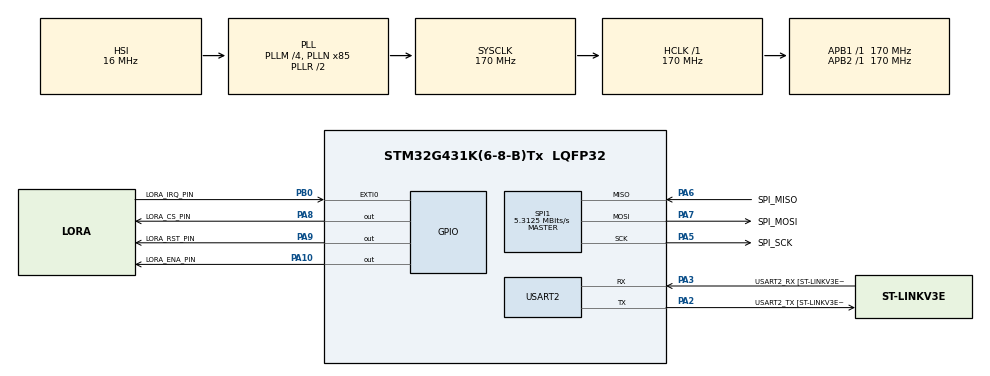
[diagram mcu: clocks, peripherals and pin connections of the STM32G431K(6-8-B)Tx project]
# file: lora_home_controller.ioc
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Mcu.Family=STM32G4
Mcu.Name=STM32G431K(6-8-B)Tx
Mcu.Package=LQFP32
NVIC.EXTI0_IRQn=true\:0\:0\:false\:false\:true\:true\:true\:true
NVIC.PriorityGroup=NVIC_PRIORITYGROUP_4
NVIC.SPI1_IRQn=true\:0\:0\:false\:false\:true\:true\:true\:true
NVIC.USART2_IRQn=true\:0\:0\:false\:false\:true\:true\:true\:true
PA10.GPIO_Label=LORA_ENA_PIN
PA10.Signal=GPIO_Output
PA13.GPIO_Label=T_SWDIO
PA13.Signal=SYS_JTMS-SWDIO
PA14.GPIO_Label=T_SWCLK
PA14.Signal=SYS_JTCK-SWCLK
PA2.GPIO_Label=USART2_TX [ST-LINKV3E_VCP_RX]
PA2.Mode=Asynchronous
PA2.Signal=USART2_TX
PA3.GPIO_Label=USART2_RX [ST-LINKV3E_VCP_TX]
PA3.Mode=Asynchronous
PA3.Signal=USART2_RX
PA5.GPIO_Label=SPI_SCK
PA5.GPIO_Speed=GPIO_SPEED_FREQ_VERY_HIGH
PA5.Mode=Full_Duplex_Master
PA5.Signal=SPI1_SCK
PA6.GPIO_Label=SPI_MISO
PA6.GPIO_Speed=GPIO_SPEED_FREQ_VERY_HIGH
PA6.Mode=Full_Duplex_Master
PA6.Signal=SPI1_MISO
PA7.GPIO_Label=SPI_MOSI
PA7.GPIO_PuPd=GPIO_NOPULL
PA7.GPIO_Speed=GPIO_SPEED_FREQ_VERY_HIGH
PA7.Mode=Full_Duplex_Master
PA7.Signal=SPI1_MOSI
PA8.GPIO_Label=LORA_CS_PIN
PA8.Signal=GPIO_Output
PA9.GPIO_Label=LORA_RST_PIN
PA9.Signal=GPIO_Output
PB0.GPIO_Label=LORA_IRQ_PIN
PB0.Signal=GPXTI0
PB3.GPIO_Label=T_SWO
PB3.Signal=SYS_JTDO-SWO
ProjectManager.HeapSize=0x200
ProjectManager.StackSize=0x400
ProjectManager.TargetToolchain=CMake
RCC.ADC12Freq_Value=170000000
RCC.AHBFreq_Value=170000000
RCC.APB1Freq_Value=170000000
RCC.APB1TimFreq_Value=170000000
RCC.APB2Freq_Value=170000000
RCC.APB2TimFreq_Value=170000000
RCC.CortexFreq_Value=170000000
RCC.EXTERNAL_CLOCK_VALUE=12288000
RCC.HCLKFreq_Value=170000000
RCC.HSE_VALUE=8000000
RCC.HSI48_VALUE=48000000
RCC.HSI_VALUE=16000000
RCC.LSE_VALUE=32768
RCC.PLLM=RCC_PLLM_DIV4
RCC.PLLN=85
RCC.SYSCLKFreq_VALUE=170000000
RCC.SYSCLKSource=RCC_SYSCLKSOURCE_PLLCLK
RCC.USBFreq_Value=170000000
RCC.VCOOutputFreq_Value=340000000
SPI1.BaudRatePrescaler=SPI_BAUDRATEPRESCALER_32
SPI1.CalculateBaudRate=5.3125 MBits/s
SPI1.DataSize=SPI_DATASIZE_8BIT
SPI1.Direction=SPI_DIRECTION_2LINES
SPI1.Mode=SPI_MODE_MASTER
SPI1.VirtualType=VM_MASTER
USART2.VirtualMode-Asynchronous=VM_ASYNC
VP_SYS_VS_DBSignals.Mode=DisableDeadBatterySignals
board=NUCLEO-G431KB

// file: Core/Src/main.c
/* USER CODE BEGIN Header */
/**
  ******************************************************************************
  * @file           : main.c
  * @brief          : Main program body
  ******************************************************************************
  * @attention
  *
  * Copyright (c) 2025 STMicroelectronics.
  * All rights reserved.
  *
  * This software is licensed under terms that can be found in the LICENSE file
  * in the root directory of this software component.
  * If no LICENSE file comes with this software, it is provided AS-IS.
  *
  ******************************************************************************
  */
/* USER CODE END Header */
#include "main.h"
#include "LoRa.h"
#include "lora_engine.h"
#include "spi.h"
#include "stm32g4xx_hal.h"
#include "usart.h"
#include "gpio.h"

/* USER CODE BEGIN PD */
#define MY_NODE_ID 1
// #define MY_NODE_ID 2

LoRa lora;
LoraDriver lora_driver;
LoraEngine lora_engine;

uint8_t lora_receive_flag = 0;
/* USER CODE END PD */

/* USER CODE BEGIN PM */
uint8_t lora_driver_transmit_func(uint8_t* data, uint8_t length, uint16_t timeout)
{
    return LoRa_single_transmit(&lora, data, length, timeout);
}
/* USER CODE END PM */

void SystemClock_Config(void);

/* USER CODE BEGIN 0 */
void HAL_GPIO_EXTI_Callback(uint16_t GPIO_Pin)
{
  if (GPIO_Pin == LORA_IRQ_PIN_Pin)
  {
    lora_receive_flag = 1;
  }
}

/* USER CODE END 0 */

int main(void)
{

  /* MCU Configuration--------------------------------------------------------*/

  /* Reset of all peripherals, Initializes the Flash interface and the Systick. */
  HAL_Init();

  /* Configure the system clock */
  SystemClock_Config();

  /* Initialize all configured peripherals */
  MX_GPIO_Init();
  MX_SPI1_Init();
  MX_USART2_UART_Init();

  /* Infinite loop */
  /* USER CODE BEGIN WHILE */

  // STEP 1) setup lora object
  // if(!SetupLoraWithPins(&lora,
  //     LORA_CS_PIN_GPIO_Port,
  //     LORA_CS_PIN_Pin,
  //     LORA_RST_PIN_GPIO_Port,
  //     LORA_RST_PIN_Pin,
  //     LORA_IRQ_PIN_GPIO_Port,
  //     LORA_IRQ_PIN_Pin,
  //     LORA_ENA_PIN_GPIO_Port,
  //     LORA_ENA_PIN_Pin,
  //     &hspi1))
  // {
  //   Error_Handler();
  // }
  // // STEP 2) SETUP LORA DRIVER
  // lora_driver.lora_ctx = (void *) &lora;
  // lora_driver.local_id = MY_NODE_ID;
  // lora_driver.transmit = lora_driver_transmit_func;

  // // STEP 3) setup ping handler object to pass the engine
  // simple_ping_handler_init(&simple_lora_handler, &lora_driver, MY_NODE_ID);

  // // STEP 4) setup lora engine
  // lora_engine_init(&lora_engine, &lora_driver, &simple_lora_handler);

  while (1)
  {
    /* USER CODE END WHILE */
    // HAL_Delay(3000);
    // lora_engine_send_ping(&lora_engine, LORA_NODE_BROADCAST_ID, 200);
    // if(lora_receive_flag)
    // {
    //   uint8_t received_data[256];
    //   uint8_t packet_size = 0;
    //   /// TURN THIS INTO lora_engine_receive because lora engine has the driver, add receive to driver
    //   packet_size = LoRa_receive(&lora, received_data, sizeof(received_data));
    //   LoraMessage msg;
    //   if(!lora_decode(received_data, sizeof(received_data), &msg))
    //   {
    //     lora_engine_handle_message(&lora_engine, &msg);
    //   }
    // }
  }
}

void SystemClock_Config(void)
{
  RCC_OscInitTypeDef RCC_OscInitStruct = {0};
  RCC_ClkInitTypeDef RCC_ClkInitStruct = {0};

  /** Configure the main internal regulator output voltage
  */
  HAL_PWREx_ControlVoltageScaling(PWR_REGULATOR_VOLTAGE_SCALE1_BOOST);

  /** Initializes the RCC Oscillators according to the specified parameters
  * in the RCC_OscInitTypeDef structure.
  */
  RCC_OscInitStruct.OscillatorType = RCC_OSCILLATORTYPE_HSI;
  RCC_OscInitStruct.HSIState = RCC_HSI_ON;
  RCC_OscInitStruct.HSICalibrationValue = RCC_HSICALIBRATION_DEFAULT;
  RCC_OscInitStruct.PLL.PLLState = RCC_PLL_ON;
  RCC_OscInitStruct.PLL.PLLSource = RCC_PLLSOURCE_HSI;
  RCC_OscInitStruct.PLL.PLLM = RCC_PLLM_DIV4;
  RCC_OscInitStruct.PLL.PLLN = 85;
  RCC_OscInitStruct.PLL.PLLP = RCC_PLLP_DIV2;
  RCC_OscInitStruct.PLL.PLLQ = RCC_PLLQ_DIV2;
  RCC_OscInitStruct.PLL.PLLR = RCC_PLLR_DIV2;
  if (HAL_RCC_OscConfig(&RCC_OscInitStruct) != HAL_OK)
  {
    Error_Handler();
  }

  /** Initializes the CPU, AHB and APB buses clocks
  */
  RCC_ClkInitStruct.ClockType = RCC_CLOCKTYPE_HCLK|RCC_CLOCKTYPE_SYSCLK
                              |RCC_CLOCKTYPE_PCLK1|RCC_CLOCKTYPE_PCLK2;
  RCC_ClkInitStruct.SYSCLKSource = RCC_SYSCLKSOURCE_PLLCLK;
  RCC_ClkInitStruct.AHBCLKDivider = RCC_SYSCLK_DIV1;
  RCC_ClkInitStruct.APB1CLKDivider = RCC_HCLK_DIV1;
  RCC_ClkInitStruct.APB2CLKDivider = RCC_HCLK_DIV1;

  if (HAL_RCC_ClockConfig(&RCC_ClkInitStruct, FLASH_LATENCY_4) != HAL_OK)
  {
    Error_Handler();
  }
}

void Error_Handler(void)
{
  /* USER CODE BEGIN Error_Handler_Debug */
  /* User can add his own implementation to report the HAL error return state */
  __disable_irq();
  uart_print("A fatal error occurred....");
  while (1)
  {

  }
  /* USER CODE END Error_Handler_Debug */
}
